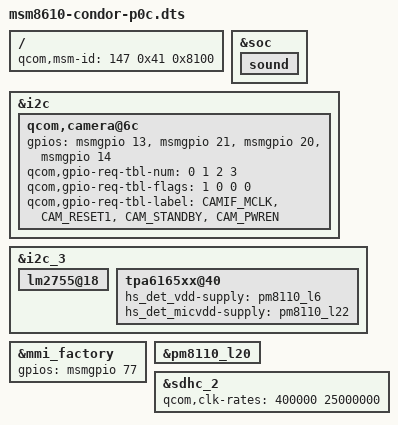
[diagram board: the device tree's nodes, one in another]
/* Copyright (c) 2013, The Linux Foundation. All rights reserved.
 *
 * This program is free software; you can redistribute it and/or modify
 * it under the terms of the GNU General Public License version 2 and
 * only version 2 as published by the Free Software Foundation.
 *
 * This program is distributed in the hope that it will be useful,
 * but WITHOUT ANY WARRANTY; without even the implied warranty of
 * MERCHANTABILITY or FITNESS FOR A PARTICULAR PURPOSE.  See the
 * GNU General Public License for more details.
 */

/dts-v1/;

/include/ "msm8610-moto-reserve.dtsi"
/include/ "msm8610-v1.dtsi"
/include/ "msm8610-moto-common.dtsi"

/ {
	qcom,msm-id = <147 0x41 0x8100>;
};

&soc {
	/delete-node/ fan5646_vreg;
	/delete-node/ fan5646;

	sound {
		/delete-property/ qcom,ext-spk-amp-gpio;
		/delete-property/ boost-supply;
	};

};

&i2c {
	qcom,camera@6c {
		gpios = <&msmgpio 13 0>,
			<&msmgpio 21 0>,
			<&msmgpio 20 0>,
			<&msmgpio 14 0>;
		/delete-property/ qcom,gpio-pwren2;
		qcom,gpio-req-tbl-num = <0 1 2 3>;
		qcom,gpio-req-tbl-flags = <1 0 0 0>;
		qcom,gpio-req-tbl-label = "CAMIF_MCLK",
			 "CAM_RESET1",
			 "CAM_STANDBY",
			 "CAM_PWREN";
	};
};

&i2c_3 {
	lm2755@18 {
		status = "ok";
	};

	tpa6165xx@40 {
		hs_det_vdd-supply = <&pm8110_l6>;
		hs_det_micvdd-supply = <&pm8110_l22>;
	};
};

/* Support Gipper factory IC */
&mmi_factory {
	gpios = <&msmgpio 77 0x2>; /* GPIOF_DIR_OUT | GPIOF_INIT_HIGH */
};

&pm8110_l20 {
	/delete-property/ regulator-always-on;
};

/* limit clock speed by 25MHz due to signal integrity issues in HS mode */
&sdhc_2 {
	qcom,clk-rates = <400000 25000000>;
};
